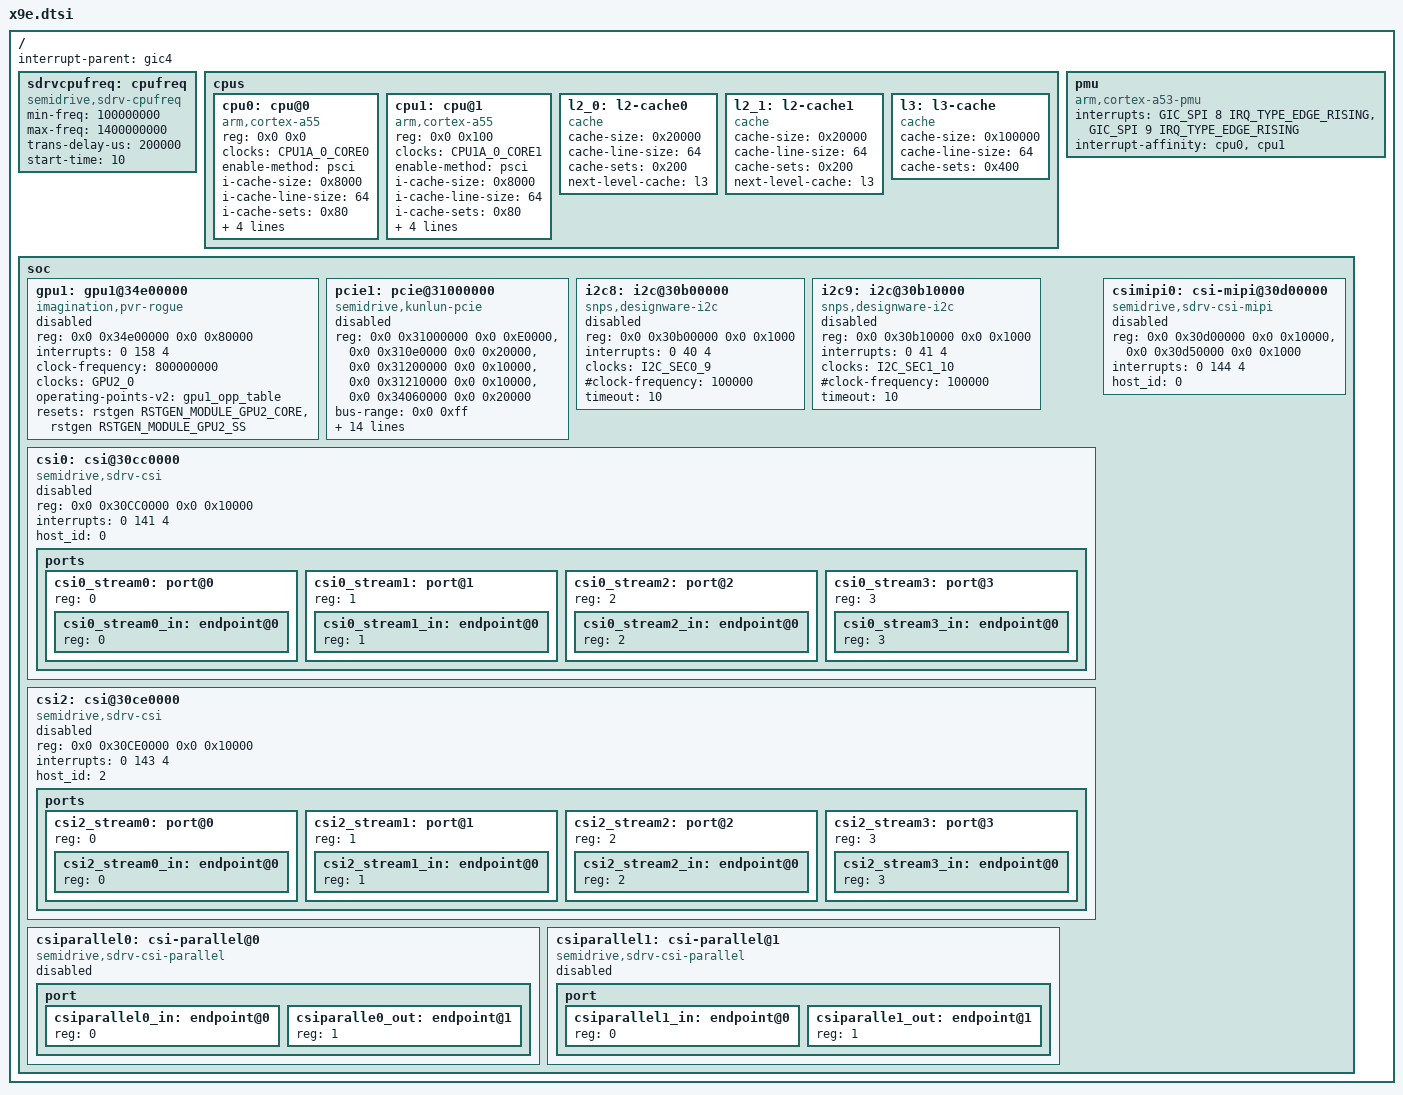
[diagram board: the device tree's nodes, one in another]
/*
* Semidrive X9 platform DTS file
*
* Copyright (C) 2019, Semidrive  Communications Inc.
*
* This file is licensed under a dual GPLv2 or X11 license.
*/
#include "x9.dtsi"
#include "x9-reset-base.dtsi"
#include "gic4_int_diff.dtsi"
#include "sdrv-coresight-cpu1-eco.dtsi"

/{
    interrupt-parent=<&gic4>;

	sdrvcpufreq: cpufreq {
		compatible = "semidrive,sdrv-cpufreq";
		min-freq = <100000000>;/*hz*/
		max-freq = <1400000000>;
		trans-delay-us = <200000>;
		start-time = <10>; /*second*/
		status = "okay";
	};

    cpus {
		#address-cells = <2>;
		#size-cells = <0>;

		/* AP1 */
		cpu0: cpu@0 {
			device_type = "cpu";
			compatible = "arm,cortex-a55", "arm,armv8";
			reg = <0x0 0x0>;
			clocks = <&CPU1A_0_CORE0>;
			clock-names = "cpu0";
			enable-method = "psci";
			i-cache-size = <0x8000>;
			i-cache-line-size = <64>;
			i-cache-sets = <0x80>;
			d-cache-size = <0x8000>;
			d-cache-line-size = <64>;
			d-cache-sets = <0x80>;
			next-level-cache = <&l2_0>;
		};

		cpu1: cpu@1 {
			device_type = "cpu";
			compatible = "arm,cortex-a55", "arm,armv8";
			reg = <0x0 0x100>;
			clocks = <&CPU1A_0_CORE1>;
			clock-names = "cpu1";
			enable-method = "psci";
			i-cache-size = <0x8000>;
			i-cache-line-size = <64>;
			i-cache-sets = <0x80>;
			d-cache-size = <0x8000>;
			d-cache-line-size = <64>;
			d-cache-sets = <0x80>;
			next-level-cache = <&l2_1>;
		};

		l2_0: l2-cache0 {
			compatible = "cache";
			cache-size = <0x20000>;
			cache-line-size = <64>;
			cache-sets = <0x200>;
			next-level-cache = <&l3>;
		};

		l2_1: l2-cache1 {
			compatible = "cache";
			cache-size = <0x20000>;
			cache-line-size = <64>;
			cache-sets = <0x200>;
			next-level-cache = <&l3>;
		};

		l3: l3-cache {
			compatible = "cache";
			cache-size = <0x100000>;
			cache-line-size = <64>;
			cache-sets = <0x400>;
		};
	};

	pmu {
		compatible = "arm,cortex-a53-pmu", "arm,armv8-pmuv3";
		interrupts = 	<GIC_SPI 8 IRQ_TYPE_EDGE_RISING>,
				<GIC_SPI 9 IRQ_TYPE_EDGE_RISING>;
		interrupt-affinity = <&cpu0>, <&cpu1>;
	};

	soc{
		gpu1:gpu1@34e00000 {
				compatible = "imagination,pvr-rogue";
				reg = <0x0 0x34e00000 0x0 0x80000>;
				interrupts = <0 158 4>;
				clock-frequency = <800000000>;
				clocks = <&GPU2_0>;
				clock-names = "gpucoreclk";
				operating-points-v2 = <&gpu1_opp_table>;
				resets = <&rstgen RSTGEN_MODULE_GPU2_CORE>, <&rstgen RSTGEN_MODULE_GPU2_SS>;
				reset-names = "gpucore-reset", "gpusys-reset";
				status = "disabled";
		};

		pcie1:	pcie@31000000 {
			compatible = "semidrive,kunlun-pcie";
			reg = <0x0 0x31000000 0x0 0xE0000>,
			      <0x0 0x310e0000 0x0 0x20000>,
			      <0x0 0x31200000 0x0 0x10000>,
			      <0x0 0x31210000 0x0 0x10000>,
			      <0x0 0x34060000 0x0 0x20000>;
			reg-names = "dbi", "ctrl_ncr", "phy", "phy_ncr", "config";
			bus-range = <0x0  0xff>;
			#address-cells = <3>;
			#size-cells = <2>;
			device_type = "pci";
			ranges = <0x02000000 0x0 0x10000000 0x0 0x10000000 0x0 0x10000000
				  0x43000000 0x5 0x0 0x5 0x0 0x1 0x0>;
			num-lanes = <1>;
                        #interrupt-cells = <1>;
			interrupts = <GIC_SPI 78 IRQ_TYPE_LEVEL_HIGH>;
			interrupt-names = "msi";
			interrupt-map-mask = <0xf800 0 0 7>;
			interrupt-map = <0x0 0 0 1
					 &gic4 GIC_SPI 78 IRQ_TYPE_LEVEL_HIGH>,
					<0x0 0 0 2
					 &gic4 GIC_SPI 79 IRQ_TYPE_LEVEL_HIGH>,
					<0x0 0 0 3
					 &gic4 GIC_SPI 80 IRQ_TYPE_LEVEL_HIGH>,
					<0x0 0 0 4
					 &gic4 GIC_SPI 81 IRQ_TYPE_LEVEL_HIGH>;

			clocks = <&HIS_BUS_1>,
				 <&HIS_BUS_3_PCIE_PHY>,
				 <&HIS_BUS_2_PCIE1>,
				 <&HIS_BUS_3_PCIE1>;
			clock-names = "pcie_phy_ref", "pcie_phy_pclk",
				          "pcie_aclk", "pcie_pclk";

			ref-clk = "internal,diffbuf_on";

			status = "disabled";
		};

		i2c8: i2c@30b00000 {
			compatible = "snps,designware-i2c";
			reg = <0x0 0x30b00000 0x0 0x1000>;
			interrupts = <0 40 4>;
			#address-cells = <1>;
			#size-cells = <0>;
			clocks=<&I2C_SEC0_9>;
			clock-names = "i2c-clk";
			#clock-frequency = <100000>;
			timeout = <10>; /* ms */
			status = "disabled";
		};

		i2c9: i2c@30b10000 {
			compatible = "snps,designware-i2c";
			reg = <0x0 0x30b10000 0x0 0x1000>;
			interrupts = <0 41 4>;
			#address-cells = <1>;
			#size-cells = <0>;
			clocks=<&I2C_SEC1_10>;
			clock-names = "i2c-clk";
			#clock-frequency = <100000>;
			timeout = <10>; /* ms */
			status = "disabled";
		};


		csi0:csi@30cc0000 {
			compatible = "semidrive,sdrv-csi";
			reg = <0x0 0x30CC0000 0x0 0x10000>;
			interrupts = <0 141 4>;
			host_id = <0>;
			status = "disabled";

			ports {
				#address-cells = <1>;
				#size-cells = <0>;

				csi0_stream0: port@0 {
					#address-cells = <1>;
					#size-cells = <0>;
					reg = <0>;
					csi0_stream0_in: endpoint@0 {
						reg = <0>;
					};
				};

				csi0_stream1: port@1 {
					#address-cells = <1>;
					#size-cells = <0>;
					reg = <1>;
					csi0_stream1_in: endpoint@0 {
						reg = <1>;
					};
				};

				csi0_stream2: port@2 {
					#address-cells = <1>;
					#size-cells = <0>;
					reg = <2>;
					csi0_stream2_in: endpoint@0 {
						reg = <2>;
					};
				};

				csi0_stream3: port@3 {
					#address-cells = <1>;
					#size-cells = <0>;
					reg = <3>;
					csi0_stream3_in: endpoint@0 {
						reg = <3>;
					};
				};
			};
		};
		csi2:csi@30ce0000 {
			compatible = "semidrive,sdrv-csi";
			reg = <0x0 0x30CE0000 0x0 0x10000>;
			interrupts = <0 143 4>;
			host_id = <2>;
			status = "disabled";

			ports {
				#address-cells = <1>;
				#size-cells = <0>;

				csi2_stream0: port@0 {
					#address-cells = <1>;
					#size-cells = <0>;
					reg = <0>;
					csi2_stream0_in: endpoint@0 {
						reg = <0>;
					};
				};

				csi2_stream1: port@1 {
					#address-cells = <1>;
					#size-cells = <0>;
					reg = <1>;
					csi2_stream1_in: endpoint@0 {
						reg = <1>;
					};
				};

				csi2_stream2: port@2 {
					#address-cells = <1>;
					#size-cells = <0>;
					reg = <2>;
					csi2_stream2_in: endpoint@0 {
						reg = <2>;
					};
				};

				csi2_stream3: port@3 {
					#address-cells = <1>;
					#size-cells = <0>;
					reg = <3>;
					csi2_stream3_in: endpoint@0 {
						reg = <3>;
					};
				};
			};
		};

		csimipi0:csi-mipi@30d00000 {
			compatible = "semidrive,sdrv-csi-mipi";
			reg = <0x0 0x30d00000 0x0 0x10000>, <0x0 0x30d50000 0x0 0x1000>;
			interrupts = <0 144 4>;
			host_id = <0>;
			status = "disabled";

			/*port {
				#address-cells = <1>;
				#size-cells = <0>;

				csimipi0_0_in: endpoint@0 {
					reg = <0>;
				};

				csimipi0_0_out: endpoint@1 {
					reg = <1>;
				};
			};*/
		};

		csiparallel0:csi-parallel@0 {
			compatible = "semidrive,sdrv-csi-parallel";
			status = "disabled";

			port {
				#address-cells = <1>;
				#size-cells = <0>;

				csiparallel0_in: endpoint@0 {
					reg = <0>;
				};

				csiparalle0_out: endpoint@1 {
					reg = <1>;
				};
			};
		};

		csiparallel1:csi-parallel@1 {
			compatible = "semidrive,sdrv-csi-parallel";
			status = "disabled";

			port {
				#address-cells = <1>;
				#size-cells = <0>;

				csiparallel1_in: endpoint@0 {
					reg = <0>;
				};

				csiparalle1_out: endpoint@1 {
					reg = <1>;
				};
			};
		};

    };
};

#include "x9e-sid.dtsi"
